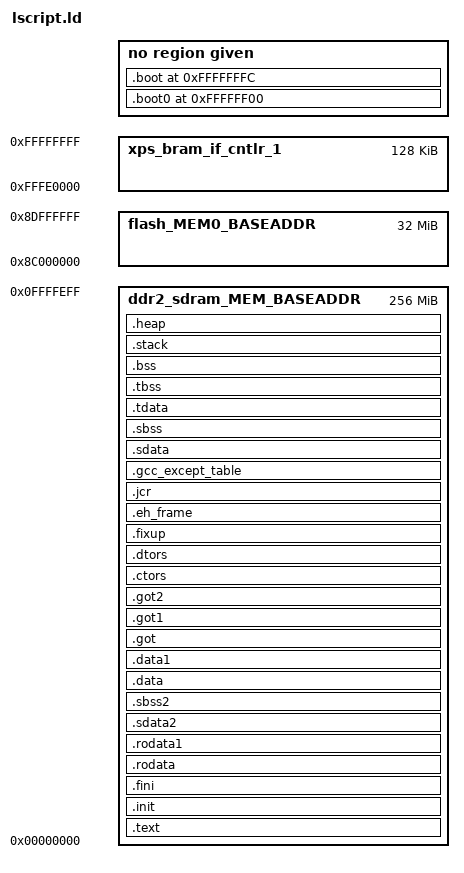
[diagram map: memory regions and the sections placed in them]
/*******************************************************************/
/*                                                                 */
/* This file is automatically generated by linker script generator.*/
/*                                                                 */
/* Version: Xilinx EDK 14.3 EDK_P.40xd                                */
/*                                                                 */
/* Copyright (c) 2010 Xilinx, Inc.  All rights reserved.           */
/*                                                                 */
/* Description : PowerPC440 Linker Script                          */
/*                                                                 */
/*******************************************************************/

_STACK_SIZE = DEFINED(_STACK_SIZE) ? _STACK_SIZE : 0x400;
_HEAP_SIZE = DEFINED(_HEAP_SIZE) ? _HEAP_SIZE : 0x400;
/* Define Memories in the system */

MEMORY
{
   xps_bram_if_cntlr_1 : ORIGIN = 0xFFFE0000, LENGTH = 0x00020000
   flash_MEM0_BASEADDR : ORIGIN = 0x8C000000, LENGTH = 0x02000000
   ddr2_sdram_MEM_BASEADDR : ORIGIN = 0x00000000, LENGTH = 0x0FFFFF00
}

/* Specify the default entry point to the program */

ENTRY(_boot)
STARTUP(boot.o)

/* Define the sections, and where they are mapped in memory */

SECTIONS
{
.text : {
   *(.text)
   *(.text.*)
   *(.gnu.linkonce.t.*)
} > ddr2_sdram_MEM_BASEADDR

.init : {
   KEEP (*(.init))
} > ddr2_sdram_MEM_BASEADDR

.fini : {
   KEEP (*(.fini))
} > ddr2_sdram_MEM_BASEADDR

.rodata : {
   __rodata_start = .;
   *(.rodata)
   *(.rodata.*)
   *(.gnu.linkonce.r.*)
   __rodata_end = .;
} > ddr2_sdram_MEM_BASEADDR

.rodata1 : {
   __rodata1_start = .;
   *(.rodata1)
   *(.rodata1.*)
   __rodata1_end = .;
} > ddr2_sdram_MEM_BASEADDR

.sdata2 : {
   __sdata2_start = .;
   *(.sdata2)
   *(.sdata2.*)
   *(.gnu.linkonce.s2.*)
   __sdata2_end = .;
} > ddr2_sdram_MEM_BASEADDR

.sbss2 : {
   __sbss2_start = .;
   *(.sbss2)
   *(.sbss2.*)
   *(.gnu.linkonce.sb2.*)
   __sbss2_end = .;
} > ddr2_sdram_MEM_BASEADDR

.data : {
   __data_start = .;
   *(.data)
   *(.data.*)
   *(.gnu.linkonce.d.*)
   __data_end = .;
} > ddr2_sdram_MEM_BASEADDR

.data1 : {
   __data1_start = .;
   *(.data1)
   *(.data1.*)
   __data1_end = .;
} > ddr2_sdram_MEM_BASEADDR

.got : {
   *(.got)
} > ddr2_sdram_MEM_BASEADDR

.got1 : {
   *(.got1)
} > ddr2_sdram_MEM_BASEADDR

.got2 : {
   *(.got2)
} > ddr2_sdram_MEM_BASEADDR

.ctors : {
   __CTOR_LIST__ = .;
   ___CTORS_LIST___ = .;
   KEEP (*crtbegin.o(.ctors))
   KEEP (*(EXCLUDE_FILE(*crtend.o) .ctors))
   KEEP (*(SORT(.ctors.*)))
   KEEP (*(.ctors))
   __CTOR_END__ = .;
   ___CTORS_END___ = .;
} > ddr2_sdram_MEM_BASEADDR

.dtors : {
   __DTOR_LIST__ = .;
   ___DTORS_LIST___ = .;
   KEEP (*crtbegin.o(.dtors))
   KEEP (*(EXCLUDE_FILE(*crtend.o) .dtors))
   KEEP (*(SORT(.dtors.*)))
   KEEP (*(.dtors))
   __DTOR_END__ = .;
   ___DTORS_END___ = .;
} > ddr2_sdram_MEM_BASEADDR

.fixup : {
   __fixup_start = .;
   *(.fixup)
   __fixup_end = .;
} > ddr2_sdram_MEM_BASEADDR

.eh_frame : {
   *(.eh_frame)
} > ddr2_sdram_MEM_BASEADDR

.jcr : {
   *(.jcr)
} > ddr2_sdram_MEM_BASEADDR

.gcc_except_table : {
   *(.gcc_except_table)
} > ddr2_sdram_MEM_BASEADDR

.sdata : {
   __sdata_start = .;
   *(.sdata)
   *(.sdata.*)
   *(.gnu.linkonce.s.*)
   __sdata_end = .;
} > ddr2_sdram_MEM_BASEADDR

.sbss (NOLOAD) : {
   . = ALIGN(4);
   __sbss_start = .;
   *(.sbss)
   *(.sbss.*)
   *(.gnu.linkonce.sb.*)
   *(.scommon)
   . = ALIGN(4);
   __sbss_end = .;
} > ddr2_sdram_MEM_BASEADDR

.tdata : {
   __tdata_start = .;
   *(.tdata)
   *(.tdata.*)
   *(.gnu.linkonce.td.*)
   __tdata_end = .;
} > ddr2_sdram_MEM_BASEADDR

.tbss : {
   __tbss_start = .;
   *(.tbss)
   *(.tbss.*)
   *(.gnu.linkonce.tb.*)
   __tbss_end = .;
} > ddr2_sdram_MEM_BASEADDR

.bss (NOLOAD) : {
   . = ALIGN(4);
   __bss_start = .;
   *(.bss)
   *(.bss.*)
   *(.gnu.linkonce.b.*)
   *(COMMON)
   . = ALIGN(4);
   __bss_end = .;
} > ddr2_sdram_MEM_BASEADDR

.boot0 0xFFFFFF00 : {
   __boot0_start = .;
   *(.boot0)
   __boot0_end = .;
} 

.boot 0xFFFFFFFC : {
   __boot_start = .;
   *(.boot)
   __boot_end = .;
} 

/* Generate Stack and Heap Sections */

.stack (NOLOAD) : {
   _stack_end = .;
   . += _STACK_SIZE;
   . = ALIGN(16);
   __stack = .;
} > ddr2_sdram_MEM_BASEADDR

.heap (NOLOAD) : {
   . = ALIGN(16);
   _heap_start = .;
   . += _HEAP_SIZE;
   . = ALIGN(16);
   _heap_end = .;
   _end = .;
} > ddr2_sdram_MEM_BASEADDR

}

